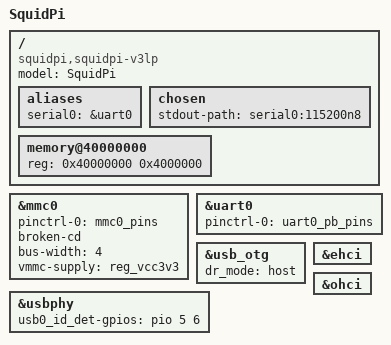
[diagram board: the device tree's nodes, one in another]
/dts-v1/;
#include "sun8i-v3s.dtsi"
#include "allwinner/sunxi-common-regulators.dtsi"

/ {
	model = "SquidPi";
	compatible = "squidpi,squidpi-v3lp", "allwinner,sun8i-v3s";

	aliases {
		serial0 = &uart0;
	};

	chosen {
		stdout-path = "serial0:115200n8";
	};

	memory@40000000 {
		device_type = "memory";
		reg = <0x40000000 0x4000000>;
	};
};

&mmc0 {
	pinctrl-names = "default";
	pinctrl-0 = <&mmc0_pins>;
	broken-cd;
	bus-width = <4>;
	vmmc-supply = <&reg_vcc3v3>;
	status = "okay";
};

&uart0 {
	pinctrl-0 = <&uart0_pb_pins>;
	pinctrl-names = "default";
	status = "okay";
};

&usb_otg {
	dr_mode = "host";
	status = "okay";
};

&usbphy {
	usb0_id_det-gpios = <&pio 5 6 GPIO_ACTIVE_HIGH>;
	status = "okay";
};

&ehci {
	status = "okay";
};

&ohci {
	status = "okay";
};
